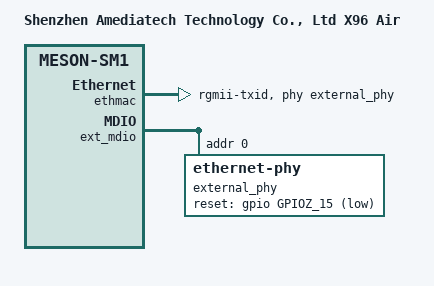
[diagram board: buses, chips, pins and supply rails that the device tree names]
// SPDX-License-Identifier: (GPL-2.0+ OR MIT)
/*
 * Copyright (c) 2019 BayLibre SAS. All rights reserved.
 * Copyright (c) 2020 Christian Hewitt <christianshewitt@gmail.com>
 */

/dts-v1/;

#include "meson-sm1-ac2xx.dtsi"

/ {
	compatible = "amediatech,x96-air-gbit", "amlogic,sm1";
	model = "Shenzhen Amediatech Technology Co., Ltd X96 Air";
};

&ethmac {
	status = "okay";

	pinctrl-0 = <&eth_pins>, <&eth_rgmii_pins>;
	pinctrl-names = "default";
	phy-mode = "rgmii-txid";
	phy-handle = <&external_phy>;

	rx-internal-delay-ps = <800>;
};

&ext_mdio {
	external_phy: ethernet-phy@0 {
		/* Realtek RTL8211F (0x001cc916) */
		reg = <0>;
		max-speed = <1000>;

		reset-assert-us = <10000>;
		reset-deassert-us = <80000>;
		reset-gpios = <&gpio GPIOZ_15 (GPIO_ACTIVE_LOW | GPIO_OPEN_DRAIN)>;

		interrupt-parent = <&gpio_intc>;
		/* MAC_INTR on GPIOZ_14 */
		interrupts = <IRQID_GPIOZ_14 IRQ_TYPE_LEVEL_LOW>;
	};
};

&ir {
	linux,rc-map-name = "rc-x96max";
};
